AUTOSAR XML (schema 4-2-2)
package /STELLANTIS/EPT/ASWCs
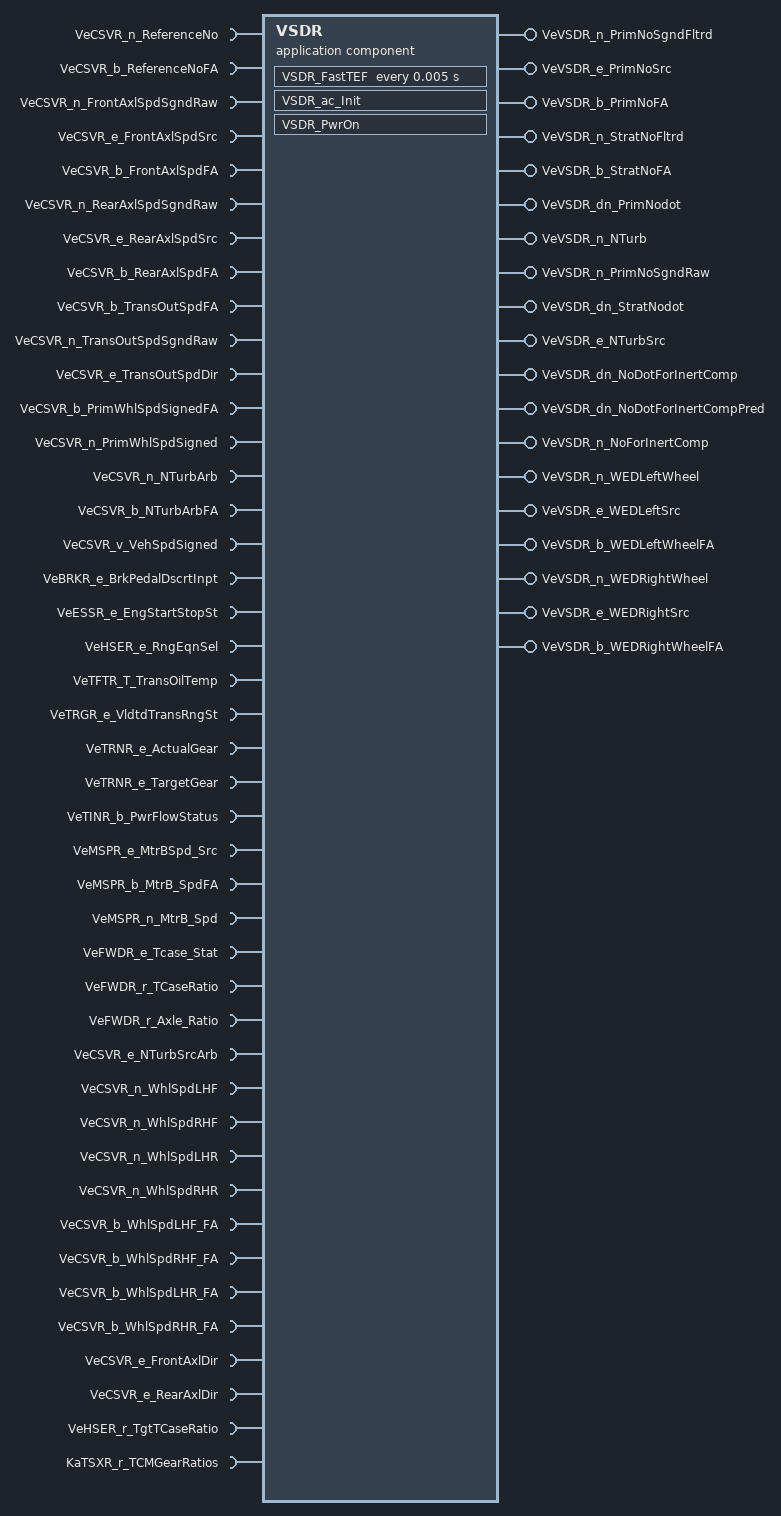
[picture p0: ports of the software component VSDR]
  application sw component type VSDR
    42 x require port:
      VeCSVR_n_ReferenceNo: nonqueued-receiver-com-spec{data-element=Value, init-value=0}, required-interface=VeCSVR_n_ReferenceNo
      VeCSVR_b_ReferenceNoFA: nonqueued-receiver-com-spec{data-element=Value, init-value=0}, required-interface=VeCSVR_b_ReferenceNoFA
      VeCSVR_n_FrontAxlSpdSgndRaw: nonqueued-receiver-com-spec{data-element=Value, init-value=0}, required-interface=VeCSVR_n_FrontAxlSpdSgndRaw
      VeCSVR_e_FrontAxlSpdSrc: nonqueued-receiver-com-spec{data-element=Value, init-value=CeCSVR_e_NoValidFASSrcAvail}, required-interface=VeCSVR_e_FrontAxlSpdSrc
      VeCSVR_b_FrontAxlSpdFA: nonqueued-receiver-com-spec{data-element=Value, init-value=0}, required-interface=VeCSVR_b_FrontAxlSpdFA
      VeCSVR_n_RearAxlSpdSgndRaw: nonqueued-receiver-com-spec{data-element=Value, init-value=0}, required-interface=VeCSVR_n_RearAxlSpdSgndRaw
      VeCSVR_e_RearAxlSpdSrc: nonqueued-receiver-com-spec{data-element=Value, init-value=CeCSVR_e_NoValidRASSrcAvail}, required-interface=VeCSVR_e_RearAxlSpdSrc
      VeCSVR_b_RearAxlSpdFA: nonqueued-receiver-com-spec{data-element=Value, init-value=0}, required-interface=VeCSVR_b_RearAxlSpdFA
      VeCSVR_b_TransOutSpdFA: nonqueued-receiver-com-spec{data-element=Value, init-value=0}, required-interface=VeCSVR_b_TransOutSpdFA
      VeCSVR_n_TransOutSpdSgndRaw: nonqueued-receiver-com-spec{data-element=Value, init-value=0}, required-interface=VeCSVR_n_TransOutSpdSgndRaw
      VeCSVR_e_TransOutSpdDir: nonqueued-receiver-com-spec{data-element=Value, init-value=CeCSVR_e_WheelDirectionUnknown}, required-interface=VeCSVR_e_TransOutSpdDir
      VeCSVR_b_PrimWhlSpdSignedFA: nonqueued-receiver-com-spec{data-element=Value, init-value=0}, required-interface=VeCSVR_b_PrimWhlSpdSignedFA
      VeCSVR_n_PrimWhlSpdSigned: nonqueued-receiver-com-spec{data-element=Value, init-value=0}, required-interface=VeCSVR_n_PrimWhlSpdSigned
      VeCSVR_n_NTurbArb: nonqueued-receiver-com-spec{data-element=Value, init-value=0}, required-interface=VeCSVR_n_NTurbArb
      VeCSVR_b_NTurbArbFA: nonqueued-receiver-com-spec{data-element=Value, init-value=0}, required-interface=VeCSVR_b_NTurbArbFA
      VeCSVR_v_VehSpdSigned: nonqueued-receiver-com-spec{data-element=Value, init-value=0}, required-interface=VeCSVR_v_VehSpdSigned
      VeBRKR_e_BrkPedalDscrtInpt: nonqueued-receiver-com-spec{data-element=Value, init-value=CeBRKR_e_BrkNotApplied}, required-interface=VeBRKR_e_BrkPedalDscrtInpt
      VeESSR_e_EngStartStopSt: nonqueued-receiver-com-spec{data-element=Value, init-value=CeESSR_e_EngOff}, required-interface=VeESSR_e_EngStartStopSt
      VeHSER_e_RngEqnSel: nonqueued-receiver-com-spec{data-element=Value, init-value=CeHSER_e_UseNeutralEqn}, required-interface=VeHSER_e_RngEqnSel
      VeTFTR_T_TransOilTemp: nonqueued-receiver-com-spec{data-element=Value, init-value=0}, required-interface=VeTFTR_T_TransOilTemp
      VeTRGR_e_VldtdTransRngSt: nonqueued-receiver-com-spec{data-element=Value, init-value=CeTRGR_e_NoSelectionAvailable}, required-interface=VeTRGR_e_VldtdTransRngSt
      VeTRNR_e_ActualGear: nonqueued-receiver-com-spec{data-element=Value, init-value=CeTRNR_e_Neutral}, required-interface=VeTRNR_e_ActualGear
      VeTRNR_e_TargetGear: nonqueued-receiver-com-spec{data-element=Value, init-value=CeTRNR_e_Neutral}, required-interface=VeTRNR_e_TargetGear
      VeTINR_b_PwrFlowStatus: nonqueued-receiver-com-spec{data-element=Value, init-value=0}, required-interface=VeTINR_b_PwrFlowStatus
      VeMSPR_e_MtrBSpd_Src: nonqueued-receiver-com-spec{data-element=Value, init-value=CeMSPR_e_MtrSpSrc_MCP}, required-interface=VeMSPR_e_MtrBSpd_Src
      VeMSPR_b_MtrB_SpdFA: nonqueued-receiver-com-spec{data-element=Value, init-value=0}, required-interface=VeMSPR_b_MtrB_SpdFA
      VeMSPR_n_MtrB_Spd: nonqueued-receiver-com-spec{data-element=Value, init-value=0}, required-interface=VeMSPR_n_MtrB_Spd
      VeFWDR_e_Tcase_Stat: nonqueued-receiver-com-spec{data-element=Value, init-value=CeFWDR_e_ShiftINProg}, required-interface=VeFWDR_e_Tcase_Stat
      VeFWDR_r_TCaseRatio: nonqueued-receiver-com-spec{data-element=Value, init-value=0}, required-interface=VeFWDR_r_TCaseRatio
      VeFWDR_r_Axle_Ratio: nonqueued-receiver-com-spec{data-element=Value, init-value=0}, required-interface=VeFWDR_r_Axle_Ratio
      VeCSVR_e_NTurbSrcArb: nonqueued-receiver-com-spec{data-element=Value, init-value=CeCSVR_e_NturbFromCAN}, required-interface=VeCSVR_e_NTurbSrcArb
      VeCSVR_n_WhlSpdLHF: nonqueued-receiver-com-spec{data-element=Value, init-value=0}, required-interface=VeCSVR_n_WhlSpdLHF
      VeCSVR_n_WhlSpdRHF: nonqueued-receiver-com-spec{data-element=Value, init-value=0}, required-interface=VeCSVR_n_WhlSpdRHF
      VeCSVR_n_WhlSpdLHR: nonqueued-receiver-com-spec{data-element=Value, init-value=0}, required-interface=VeCSVR_n_WhlSpdLHR
      VeCSVR_n_WhlSpdRHR: nonqueued-receiver-com-spec{data-element=Value, init-value=0}, required-interface=VeCSVR_n_WhlSpdRHR
      VeCSVR_b_WhlSpdLHF_FA: nonqueued-receiver-com-spec{data-element=Value, init-value=0}, required-interface=VeCSVR_b_WhlSpdLHF_FA
      VeCSVR_b_WhlSpdRHF_FA: nonqueued-receiver-com-spec{data-element=Value, init-value=0}, required-interface=VeCSVR_b_WhlSpdRHF_FA
      VeCSVR_b_WhlSpdLHR_FA: nonqueued-receiver-com-spec{data-element=Value, init-value=0}, required-interface=VeCSVR_b_WhlSpdLHR_FA
      VeCSVR_b_WhlSpdRHR_FA: nonqueued-receiver-com-spec{data-element=Value, init-value=0}, required-interface=VeCSVR_b_WhlSpdRHR_FA
      VeCSVR_e_FrontAxlDir: nonqueued-receiver-com-spec{data-element=Value, init-value=CeCSVR_e_WheelDirectionUnknown}, required-interface=VeCSVR_e_FrontAxlDir
      VeCSVR_e_RearAxlDir: nonqueued-receiver-com-spec{data-element=Value, init-value=CeCSVR_e_WheelDirectionUnknown}, required-interface=VeCSVR_e_RearAxlDir
      VeHSER_r_TgtTCaseRatio: nonqueued-receiver-com-spec{data-element=Value, init-value=0}, required-interface=VeHSER_r_TgtTCaseRatio
    19 x provide port:
      VeVSDR_n_PrimNoSgndFltrd: nonqueued-sender-com-spec{data-element=Value, init-value=0}, provided-interface=VeVSDR_n_PrimNoSgndFltrd
      VeVSDR_e_PrimNoSrc: nonqueued-sender-com-spec{data-element=Value, init-value=CeVSDR_e_PrimNoSrcNotAvail}, provided-interface=VeVSDR_e_PrimNoSrc
      VeVSDR_b_PrimNoFA: nonqueued-sender-com-spec{data-element=Value, init-value=0}, provided-interface=VeVSDR_b_PrimNoFA
      VeVSDR_n_StratNoFltrd: nonqueued-sender-com-spec{data-element=Value, init-value=0}, provided-interface=VeVSDR_n_StratNoFltrd
      VeVSDR_b_StratNoFA: nonqueued-sender-com-spec{data-element=Value, init-value=0}, provided-interface=VeVSDR_b_StratNoFA
      VeVSDR_dn_PrimNodot: nonqueued-sender-com-spec{data-element=Value, init-value=0}, provided-interface=VeVSDR_dn_PrimNodot
      VeVSDR_n_NTurb: nonqueued-sender-com-spec{data-element=Value, init-value=0}, provided-interface=VeVSDR_n_NTurb
      VeVSDR_n_PrimNoSgndRaw: nonqueued-sender-com-spec{data-element=Value, init-value=0}, provided-interface=VeVSDR_n_PrimNoSgndRaw
      VeVSDR_dn_StratNodot: nonqueued-sender-com-spec{data-element=Value, init-value=0}, provided-interface=VeVSDR_dn_StratNodot
      VeVSDR_e_NTurbSrc: nonqueued-sender-com-spec{data-element=Value, init-value=CeVSDR_e_NturbFromCSVR_CAN}, provided-interface=VeVSDR_e_NTurbSrc
      VeVSDR_dn_NoDotForInertComp: nonqueued-sender-com-spec{data-element=Value, init-value=0}, provided-interface=VeVSDR_dn_NoDotForInertComp
      VeVSDR_dn_NoDotForInertCompPred: nonqueued-sender-com-spec{data-element=Value, init-value=0}, provided-interface=VeVSDR_dn_NoDotForInertCompPred
      VeVSDR_n_NoForInertComp: nonqueued-sender-com-spec{data-element=Value, init-value=0}, provided-interface=VeVSDR_n_NoForInertComp
      VeVSDR_n_WEDLeftWheel: nonqueued-sender-com-spec{data-element=Value, init-value=0}, provided-interface=VeVSDR_n_WEDLeftWheel
      VeVSDR_e_WEDLeftSrc: nonqueued-sender-com-spec{data-element=Value, init-value=CeVSDR_e_WEDWhlSpdFromFrontWhls}, provided-interface=VeVSDR_e_WEDLeftSrc
      VeVSDR_b_WEDLeftWheelFA: nonqueued-sender-com-spec{data-element=Value, init-value=0}, provided-interface=VeVSDR_b_WEDLeftWheelFA
      VeVSDR_n_WEDRightWheel: nonqueued-sender-com-spec{data-element=Value, init-value=0}, provided-interface=VeVSDR_n_WEDRightWheel
      VeVSDR_e_WEDRightSrc: nonqueued-sender-com-spec{data-element=Value, init-value=CeVSDR_e_WEDWhlSpdFromFrontWhls}, provided-interface=VeVSDR_e_WEDRightSrc
      VeVSDR_b_WEDRightWheelFA: nonqueued-sender-com-spec{data-element=Value, init-value=0}, provided-interface=VeVSDR_b_WEDRightWheelFA
    require port KaTSXR_r_TCMGearRatios: parameter-require-com-spec{init-value=KaTSXR_r_TCMGearRatios_KaTSXR_r_TCMGearRatios:[KaTSXR_r_TCMGearRatios_KaTSXR_r_TCMGearRatios_rt_Array_Float_13_1:1, KaTSXR_r_TCMGearRatios_KaTSXR_r_TCMGearRatios_rt_Array_Float_13_2:1, KaTSXR_r_TCMGearRatios_KaTSXR_r_TCMGearRatios_rt_Array_Float_13_3:1, KaTSXR_r_TCMGearRatios_KaTSXR_r_TCMGearRatios_rt_Array_Float_13_4:1, KaTSXR_r_TCMGearRatios_KaTSXR_r_TCMGearRatios_rt_Array_Float_13_5:1, KaTSXR_r_TCMGearRatios_KaTSXR_r_TCMGearRatios_rt_Array_Float_13_6:1, KaTSXR_r_TCMGearRatios_KaTSXR_r_TCMGearRatios_rt_Array_Float_13_7:1, KaTSXR_r_TCMGearRatios_KaTSXR_r_TCMGearRatios_rt_Array_Float_13_8:1, KaTSXR_r_TCMGearRatios_KaTSXR_r_TCMGearRatios_rt_Array_Float_13_9:1, KaTSXR_r_TCMGearRatios_KaTSXR_r_TCMGearRatios_rt_Array_Float_13_10:1, KaTSXR_r_TCMGearRatios_KaTSXR_r_TCMGearRatios_rt_Array_Float_13_11:1, KaTSXR_r_TCMGearRatios_KaTSXR_r_TCMGearRatios_rt_Array_Float_13_12:1, KaTSXR_r_TCMGearRatios_KaTSXR_r_TCMGearRatios_rt_Array_Float_13_13:1], parameter=KaTSXR_r_TCMGearRatios}, required-interface=KaTSXR_r_TCMGearRatios
    behavior IB_VSDR: data-type-mapping=msADTtoIDTMapping, handle-termination-and-restart=NO-SUPPORT
      timing event Event_FastTEF: start-on-event=VSDR_FastTEF, period=0.005
      init event Event_VSDR_ac_Init: start-on-event=VSDR_ac_Init
      init event Event_PwrOn: start-on-event=VSDR_PwrOn
      runnable VSDR_ac_Init
        data-send-points:
          4 x access:
            OUT_VeVSDR_e_PrimNoSrc_Value: accessed-variable=VeVSDR_e_PrimNoSrc.Value
            OUT_VeVSDR_e_NTurbSrc_Value: accessed-variable=VeVSDR_e_NTurbSrc.Value
            OUT_VeVSDR_e_WEDLeftSrc_Value: accessed-variable=VeVSDR_e_WEDLeftSrc.Value
            OUT_VeVSDR_e_WEDRightSrc_Value: accessed-variable=VeVSDR_e_WEDRightSrc.Value
      runnable VSDR_FastTEF
        data-receive-point-by-arguments:
          42 x access:
            IN_VeBRKR_e_BrkPedalDscrtInpt_Value: accessed-variable=VeBRKR_e_BrkPedalDscrtInpt.Value
            IN_VeCSVR_b_FrontAxlSpdFA_Value: accessed-variable=VeCSVR_b_FrontAxlSpdFA.Value
            IN_VeCSVR_b_NTurbArbFA_Value: accessed-variable=VeCSVR_b_NTurbArbFA.Value
            IN_VeCSVR_b_PrimWhlSpdSignedFA_Value: accessed-variable=VeCSVR_b_PrimWhlSpdSignedFA.Value
            IN_VeCSVR_b_RearAxlSpdFA_Value: accessed-variable=VeCSVR_b_RearAxlSpdFA.Value
            IN_VeCSVR_b_ReferenceNoFA_Value: accessed-variable=VeCSVR_b_ReferenceNoFA.Value
            IN_VeCSVR_b_TransOutSpdFA_Value: accessed-variable=VeCSVR_b_TransOutSpdFA.Value
            IN_VeCSVR_b_WhlSpdLHF_FA_Value: accessed-variable=VeCSVR_b_WhlSpdLHF_FA.Value
            IN_VeCSVR_b_WhlSpdLHR_FA_Value: accessed-variable=VeCSVR_b_WhlSpdLHR_FA.Value
            IN_VeCSVR_b_WhlSpdRHF_FA_Value: accessed-variable=VeCSVR_b_WhlSpdRHF_FA.Value
            IN_VeCSVR_b_WhlSpdRHR_FA_Value: accessed-variable=VeCSVR_b_WhlSpdRHR_FA.Value
            IN_VeCSVR_e_FrontAxlDir_Value: accessed-variable=VeCSVR_e_FrontAxlDir.Value
            IN_VeCSVR_e_FrontAxlSpdSrc_Value: accessed-variable=VeCSVR_e_FrontAxlSpdSrc.Value
            IN_VeCSVR_e_NTurbSrcArb_Value: accessed-variable=VeCSVR_e_NTurbSrcArb.Value
            IN_VeCSVR_e_RearAxlDir_Value: accessed-variable=VeCSVR_e_RearAxlDir.Value
            IN_VeCSVR_e_RearAxlSpdSrc_Value: accessed-variable=VeCSVR_e_RearAxlSpdSrc.Value
            IN_VeCSVR_e_TransOutSpdDir_Value: accessed-variable=VeCSVR_e_TransOutSpdDir.Value
            IN_VeCSVR_n_FrontAxlSpdSgndRaw_Value: accessed-variable=VeCSVR_n_FrontAxlSpdSgndRaw.Value
            IN_VeCSVR_n_NTurbArb_Value: accessed-variable=VeCSVR_n_NTurbArb.Value
            IN_VeCSVR_n_PrimWhlSpdSigned_Value: accessed-variable=VeCSVR_n_PrimWhlSpdSigned.Value
            IN_VeCSVR_n_RearAxlSpdSgndRaw_Value: accessed-variable=VeCSVR_n_RearAxlSpdSgndRaw.Value
            IN_VeCSVR_n_ReferenceNo_Value: accessed-variable=VeCSVR_n_ReferenceNo.Value
            IN_VeCSVR_n_TransOutSpdSgndRaw_Value: accessed-variable=VeCSVR_n_TransOutSpdSgndRaw.Value
            IN_VeCSVR_n_WhlSpdLHF_Value: accessed-variable=VeCSVR_n_WhlSpdLHF.Value
            IN_VeCSVR_n_WhlSpdLHR_Value: accessed-variable=VeCSVR_n_WhlSpdLHR.Value
            IN_VeCSVR_n_WhlSpdRHF_Value: accessed-variable=VeCSVR_n_WhlSpdRHF.Value
            IN_VeCSVR_n_WhlSpdRHR_Value: accessed-variable=VeCSVR_n_WhlSpdRHR.Value
            IN_VeCSVR_v_VehSpdSigned_Value: accessed-variable=VeCSVR_v_VehSpdSigned.Value
            IN_VeESSR_e_EngStartStopSt_Value: accessed-variable=VeESSR_e_EngStartStopSt.Value
            IN_VeFWDR_e_Tcase_Stat_Value: accessed-variable=VeFWDR_e_Tcase_Stat.Value
            IN_VeFWDR_r_Axle_Ratio_Value: accessed-variable=VeFWDR_r_Axle_Ratio.Value
            IN_VeFWDR_r_TCaseRatio_Value: accessed-variable=VeFWDR_r_TCaseRatio.Value
            IN_VeHSER_e_RngEqnSel_Value: accessed-variable=VeHSER_e_RngEqnSel.Value
            IN_VeHSER_r_TgtTCaseRatio_Value: accessed-variable=VeHSER_r_TgtTCaseRatio.Value
            IN_VeMSPR_b_MtrB_SpdFA_Value: accessed-variable=VeMSPR_b_MtrB_SpdFA.Value
            IN_VeMSPR_e_MtrBSpd_Src_Value: accessed-variable=VeMSPR_e_MtrBSpd_Src.Value
            IN_VeMSPR_n_MtrB_Spd_Value: accessed-variable=VeMSPR_n_MtrB_Spd.Value
            IN_VeTFTR_T_TransOilTemp_Value: accessed-variable=VeTFTR_T_TransOilTemp.Value
            IN_VeTINR_b_PwrFlowStatus_Value: accessed-variable=VeTINR_b_PwrFlowStatus.Value
            IN_VeTRGR_e_VldtdTransRngSt_Value: accessed-variable=VeTRGR_e_VldtdTransRngSt.Value
            IN_VeTRNR_e_ActualGear_Value: accessed-variable=VeTRNR_e_ActualGear.Value
            IN_VeTRNR_e_TargetGear_Value: accessed-variable=VeTRNR_e_TargetGear.Value
        data-send-points:
          19 x access:
            OUT_VeVSDR_n_PrimNoSgndFltrd_Value: accessed-variable=VeVSDR_n_PrimNoSgndFltrd.Value
            OUT_VeVSDR_e_PrimNoSrc_Value: accessed-variable=VeVSDR_e_PrimNoSrc.Value
            OUT_VeVSDR_b_PrimNoFA_Value: accessed-variable=VeVSDR_b_PrimNoFA.Value
            OUT_VeVSDR_n_StratNoFltrd_Value: accessed-variable=VeVSDR_n_StratNoFltrd.Value
            OUT_VeVSDR_b_StratNoFA_Value: accessed-variable=VeVSDR_b_StratNoFA.Value
            OUT_VeVSDR_dn_PrimNodot_Value: accessed-variable=VeVSDR_dn_PrimNodot.Value
            OUT_VeVSDR_n_NTurb_Value: accessed-variable=VeVSDR_n_NTurb.Value
            OUT_VeVSDR_n_PrimNoSgndRaw_Value: accessed-variable=VeVSDR_n_PrimNoSgndRaw.Value
            OUT_VeVSDR_dn_StratNodot_Value: accessed-variable=VeVSDR_dn_StratNodot.Value
            OUT_VeVSDR_e_NTurbSrc_Value: accessed-variable=VeVSDR_e_NTurbSrc.Value
            OUT_VeVSDR_dn_NoDotForInertComp_Value: accessed-variable=VeVSDR_dn_NoDotForInertComp.Value
            OUT_VeVSDR_dn_NoDotForInertCompPred_Value: accessed-variable=VeVSDR_dn_NoDotForInertCompPred.Value
            OUT_VeVSDR_n_NoForInertComp_Value: accessed-variable=VeVSDR_n_NoForInertComp.Value
            OUT_VeVSDR_n_WEDLeftWheel_Value: accessed-variable=VeVSDR_n_WEDLeftWheel.Value
            OUT_VeVSDR_e_WEDLeftSrc_Value: accessed-variable=VeVSDR_e_WEDLeftSrc.Value
            OUT_VeVSDR_b_WEDLeftWheelFA_Value: accessed-variable=VeVSDR_b_WEDLeftWheelFA.Value
            OUT_VeVSDR_n_WEDRightWheel_Value: accessed-variable=VeVSDR_n_WEDRightWheel.Value
            OUT_VeVSDR_e_WEDRightSrc_Value: accessed-variable=VeVSDR_e_WEDRightSrc.Value
            OUT_VeVSDR_b_WEDRightWheelFA_Value: accessed-variable=VeVSDR_b_WEDRightWheelFA.Value
        parameter access CALPRM_KaTSXR_r_TCMGearRatios_KaTSXR_r_TCMGearRatios: accessed-parameter=KaTSXR_r_TCMGearRatios.KaTSXR_r_TCMGearRatios
      runnable VSDR_PwrOn
        data-send-points:
          19 x access:
            OUT_VeVSDR_n_PrimNoSgndFltrd_Value: accessed-variable=VeVSDR_n_PrimNoSgndFltrd.Value
            OUT_VeVSDR_e_PrimNoSrc_Value: accessed-variable=VeVSDR_e_PrimNoSrc.Value
            OUT_VeVSDR_b_PrimNoFA_Value: accessed-variable=VeVSDR_b_PrimNoFA.Value
            OUT_VeVSDR_n_StratNoFltrd_Value: accessed-variable=VeVSDR_n_StratNoFltrd.Value
            OUT_VeVSDR_b_StratNoFA_Value: accessed-variable=VeVSDR_b_StratNoFA.Value
            OUT_VeVSDR_dn_PrimNodot_Value: accessed-variable=VeVSDR_dn_PrimNodot.Value
            OUT_VeVSDR_n_NTurb_Value: accessed-variable=VeVSDR_n_NTurb.Value
            OUT_VeVSDR_n_PrimNoSgndRaw_Value: accessed-variable=VeVSDR_n_PrimNoSgndRaw.Value
            OUT_VeVSDR_dn_StratNodot_Value: accessed-variable=VeVSDR_dn_StratNodot.Value
            OUT_VeVSDR_e_NTurbSrc_Value: accessed-variable=VeVSDR_e_NTurbSrc.Value
            OUT_VeVSDR_dn_NoDotForInertComp_Value: accessed-variable=VeVSDR_dn_NoDotForInertComp.Value
            OUT_VeVSDR_dn_NoDotForInertCompPred_Value: accessed-variable=VeVSDR_dn_NoDotForInertCompPred.Value
            OUT_VeVSDR_n_NoForInertComp_Value: accessed-variable=VeVSDR_n_NoForInertComp.Value
            OUT_VeVSDR_n_WEDLeftWheel_Value: accessed-variable=VeVSDR_n_WEDLeftWheel.Value
            OUT_VeVSDR_e_WEDLeftSrc_Value: accessed-variable=VeVSDR_e_WEDLeftSrc.Value
            OUT_VeVSDR_b_WEDLeftWheelFA_Value: accessed-variable=VeVSDR_b_WEDLeftWheelFA.Value
            OUT_VeVSDR_n_WEDRightWheel_Value: accessed-variable=VeVSDR_n_WEDRightWheel.Value
            OUT_VeVSDR_e_WEDRightSrc_Value: accessed-variable=VeVSDR_e_WEDRightSrc.Value
            OUT_VeVSDR_b_WEDRightWheelFA_Value: accessed-variable=VeVSDR_b_WEDRightWheelFA.Value
